AUTOSAR XML (schema 00049)
# Copyright (c) 2018 Vector Informatik GmbH.
standard types defined: boolean, uint8
package /VehicleProject
  system System
package /TP
  lin tp config LIN00: communication-cluster=LIN00
    7 x tp address:
      TA_0x0001: tp-address=1
      TA_0x0002: tp-address=2
      TA_0x0003: tp-address=3
      TA_0x0004: tp-address=4
      TA_0x0005: tp-address=5
      TA_0x0006: tp-address=6
      TA_0x007E: tp-address=126
    tp-connections:
      data-pdu=MasterReq_Tp, lin-tp-n-sdu=MasterReq, multicast=TA_0x007E, receiver=[TN_0x0001_DWF_Left, TN_0x0002_DWR_Left, TN_0x0003_RVM_Left, TN_0x0004_RVM_Right, TN_0x0005_DWR_Right, TN_0x0006_DWF_Right], transmitter=TN_Master
      data-pdu=SlaveResp_Tp, flow-control=MasterReq_Tp, lin-tp-n-sdu=SlaveResp_DWF_Left, receiver=TN_Master, transmitter=TN_0x0001_DWF_Left
      data-pdu=SlaveResp_Tp, flow-control=MasterReq_Tp, lin-tp-n-sdu=SlaveResp_DWR_Left, receiver=TN_Master, transmitter=TN_0x0002_DWR_Left
      data-pdu=SlaveResp_Tp, flow-control=MasterReq_Tp, lin-tp-n-sdu=SlaveResp_RVM_Left, receiver=TN_Master, transmitter=TN_0x0003_RVM_Left
      data-pdu=SlaveResp_Tp, flow-control=MasterReq_Tp, lin-tp-n-sdu=SlaveResp_RVM_Right, receiver=TN_Master, transmitter=TN_0x0004_RVM_Right
      data-pdu=SlaveResp_Tp, flow-control=MasterReq_Tp, lin-tp-n-sdu=SlaveResp_DWR_Right, receiver=TN_Master, transmitter=TN_0x0005_DWR_Right
      data-pdu=SlaveResp_Tp, flow-control=MasterReq_Tp, lin-tp-n-sdu=SlaveResp_DWF_Right, receiver=TN_Master, transmitter=TN_0x0006_DWF_Right
      data-pdu=MasterReq_Tp, flow-control=SlaveResp_Tp, lin-tp-n-sdu=MasterReq_DWF_Left, receiver=TN_0x0001_DWF_Left, transmitter=TN_Master
      data-pdu=MasterReq_Tp, flow-control=SlaveResp_Tp, lin-tp-n-sdu=MasterReq_DWR_Left, receiver=TN_0x0002_DWR_Left, transmitter=TN_Master
      data-pdu=MasterReq_Tp, flow-control=SlaveResp_Tp, lin-tp-n-sdu=MasterReq_RVM_Left, receiver=TN_0x0003_RVM_Left, transmitter=TN_Master
      data-pdu=MasterReq_Tp, flow-control=SlaveResp_Tp, lin-tp-n-sdu=MasterReq_RVM_Right, receiver=TN_0x0004_RVM_Right, transmitter=TN_Master
      data-pdu=MasterReq_Tp, flow-control=SlaveResp_Tp, lin-tp-n-sdu=MasterReq_DWR_Right, receiver=TN_0x0005_DWR_Right, transmitter=TN_Master
      data-pdu=MasterReq_Tp, flow-control=SlaveResp_Tp, lin-tp-n-sdu=MasterReq_DWF_Right, receiver=TN_0x0006_DWF_Right, transmitter=TN_Master
    7 x lin tp node:
      TN_0x0001_DWF_Left: connector=DWF_Left/CN_LIN00, tp-address=TA_0x0001
      TN_0x0002_DWR_Left: connector=DWR_Left/CN_LIN00, tp-address=TA_0x0002
      TN_0x0003_RVM_Left: connector=RVM_Left/CN_LIN00, tp-address=TA_0x0003
      TN_0x0004_RVM_Right: connector=RVM_Right/CN_LIN00, tp-address=TA_0x0004
      TN_0x0005_DWR_Right: connector=DWR_Right/CN_LIN00, tp-address=TA_0x0005
      TN_0x0006_DWF_Right: connector=DWF_Right/CN_LIN00, tp-address=TA_0x0006
      TN_Master: connector=GWI/CN_LIN00
package /Cluster
  lin cluster LIN00: baudrate=19200, protocol-name=LIN, protocol-version=LIN22  # Door | /*************************************************************************************/ // // Description: LIN Description file created using Vector's DaVinci Network Designer // Created: 12 Oct 2007 10:43:53 // Author: Vector Informatik GmbH // Version: 0.1 // /*************************************************************************************/
    lin physical channel CHNL
      comm-connectors:
        DWF_Left/CN_LIN00
        DWF_Right/CN_LIN00
        DWR_Left/CN_LIN00
        DWR_Right/CN_LIN00
        GWI/CN_LIN00
        RVM_Left/CN_LIN00
        RVM_Right/CN_LIN00
      frame DWFL_01: id 0x3, from DWF_Left, to GWI, frame-length=2, lin-checksum=ENHANCED
        pdu DWFL_01: length=2, unused-bit-pattern=255
          signal DWFL_WinPos: start 0, 8 bit, little-endian, i-signal-type=PRIMITIVE, init-value=0, base-type=uint8, compu {identical}, range raw 0..255, to GWI
          signal DWFL_ResponseError: start 8, 1 bit, little-endian, i-signal-type=PRIMITIVE, init-value=0, base-type=boolean, compu {identical}, range raw 0..1, to GWI
      frame DWFR_01: id 0x0, from DWF_Right, to GWI, frame-length=2, lin-checksum=ENHANCED
        pdu DWFR_01: length=2, unused-bit-pattern=255
          signal DWFR_ResponseError: start 0, 1 bit, little-endian, i-signal-type=PRIMITIVE, init-value=0, base-type=boolean, compu {identical}, range raw 0..1, to GWI
          signal DWFR_WinPos: start 8, 8 bit, little-endian, i-signal-type=PRIMITIVE, init-value=0, base-type=uint8, compu {identical}, range raw 0..255, to GWI
      frame DWRL_01: id 0x2, from DWR_Left, to GWI, frame-length=2, lin-checksum=ENHANCED
        pdu DWRL_01: length=2, unused-bit-pattern=255
          signal DWRL_WinPos: start 0, 8 bit, little-endian, i-signal-type=PRIMITIVE, init-value=0, base-type=uint8, compu {identical}, range raw 0..255, to GWI
          signal DWRL_ResponseError: start 8, 1 bit, little-endian, i-signal-type=PRIMITIVE, init-value=0, base-type=boolean, compu {identical}, range raw 0..1, to GWI
      frame DWRR_01: id 0x7, from DWR_Right, to GWI, frame-length=2, lin-checksum=ENHANCED
        pdu DWRR_01: length=2, unused-bit-pattern=255
          signal DWRR_ResponseError: start 0, 1 bit, little-endian, i-signal-type=PRIMITIVE, init-value=0, base-type=boolean, compu {identical}, range raw 0..1, to GWI
          signal DWRR_WinPos: start 8, 8 bit, little-endian, i-signal-type=PRIMITIVE, init-value=0, base-type=uint8, compu {identical}, range raw 0..255, to GWI
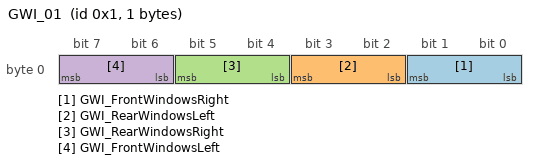
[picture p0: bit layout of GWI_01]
      frame GWI_01: id 0x1, from GWI, to DWF_Left DWF_Right DWR_Left DWR_Right, frame-length=1, lin-checksum=ENHANCED
        pdu GWI_01: length=1, unused-bit-pattern=255
          signal GWI_FrontWindowsRight: start 0, 2 bit, little-endian, i-signal-type=PRIMITIVE, init-value=1, base-type=uint8, compu {0=Cx0_Down, 1=Cx1_Halt, 2=Cx2_Up}, range raw 0..2, to DWF_Right
          signal GWI_RearWindowsLeft: start 2, 2 bit, little-endian, i-signal-type=PRIMITIVE, init-value=1, base-type=uint8, compu {0=Cx0_Down, 1=Cx1_Halt, 2=Cx2_Up}, range raw 0..2, to DWR_Left
          signal GWI_RearWindowsRight: start 4, 2 bit, little-endian, i-signal-type=PRIMITIVE, init-value=1, base-type=uint8, compu {0=Cx0_Down, 1=Cx1_Halt, 2=Cx2_Up}, range raw 0..2, to DWR_Right
          signal GWI_FrontWindowsLeft: start 6, 2 bit, little-endian, i-signal-type=PRIMITIVE, init-value=1, base-type=uint8, compu {0=Cx0_Down, 1=Cx1_Halt, 2=Cx2_Up}, range raw 0..2, to DWF_Left
      frame GWI_02: id 0x4, from GWI, to DWF_Left DWF_Right DWR_Left, frame-length=1, lin-checksum=ENHANCED
        pdu GWI_02: length=1, unused-bit-pattern=255
          signal CLSStatusLeft_oGWI_02: start 0, 1 bit, little-endian, i-signal-type=PRIMITIVE, init-value=0, base-type=boolean, compu {0=Cx0_Close, 1=Cx1_Open}, range raw 0..1, to DWF_Left DWR_Left
          signal CLSStatusRight_oGWI_02: start 1, 1 bit, little-endian, i-signal-type=PRIMITIVE, init-value=0, base-type=boolean, compu {0=Cx0_Close, 1=Cx1_Open}, range raw 0..1, to DWF_Right
      frame GWI_03: id 0x5, from GWI, to RVM_Left RVM_Right, frame-length=1, lin-checksum=ENHANCED
        pdu GWI_03: length=1, unused-bit-pattern=255
          signal GWI_MirrorCommandLeft: start 0, 4 bit, little-endian, i-signal-type=PRIMITIVE, init-value=0, base-type=uint8, compu {0=Cx0_Don_t_move (Don't move), 1=Cx1_Move_left (Move left), 2=Cx2_Move_Up (Move Up), 3=Cx3_Move_Right (Move Right), 4=Cx4_Move_Down (Move Down)}, range raw 0..4, to RVM_Left
          signal GWI_MirrorCommandRight: start 4, 4 bit, little-endian, i-signal-type=PRIMITIVE, init-value=0, base-type=uint8, compu {0=Cx0_Don_t_move (Don't move), 1=Cx1_Move_left (Move left), 2=Cx2_Move_Up (Move Up), 3=Cx3_Move_Right (Move Right), 4=Cx4_Move_Down (Move Down)}, range raw 0..4, to RVM_Right
      frame MasterReq: id 0x3C, from GWI, to DWF_Left DWF_Right DWR_Left DWR_Right RVM_Left RVM_Right, frame-length=8, lin-checksum=CLASSIC
        n pdu MasterReq_Tp: length=8
      frame RVML_01: id 0x6, from RVM_Left, to GWI, frame-length=2, lin-checksum=ENHANCED
        pdu RVML_01: length=2, unused-bit-pattern=255
          signal RVML_MirrorPosition: start 0, 8 bit, little-endian, i-signal-type=PRIMITIVE, init-value=0, base-type=uint8, compu {identical}, range raw 0..255, to GWI
          signal RVML_ResponseError: start 8, 1 bit, little-endian, i-signal-type=PRIMITIVE, init-value=0, base-type=boolean, compu {identical}, range raw 0..1, to GWI
      frame RVMR_01: id 0x8, from RVM_Right, to GWI, frame-length=2, lin-checksum=ENHANCED
        pdu RVMR_01: length=2, unused-bit-pattern=255
          signal RVMR_ResponseError: start 0, 1 bit, little-endian, i-signal-type=PRIMITIVE, init-value=0, base-type=boolean, compu {identical}, range raw 0..1, to GWI
          signal RVMR_MirrorPosition: start 8, 8 bit, little-endian, i-signal-type=PRIMITIVE, init-value=0, base-type=uint8, compu {identical}, range raw 0..255, to GWI
      frame SlaveResp: id 0x3D, from DWF_Left DWF_Right DWR_Left DWR_Right RVM_Left RVM_Right, to GWI, frame-length=8, lin-checksum=CLASSIC
        n pdu SlaveResp_Tp: length=8
      pdu triggering PT_MasterReq: pdu=MasterReq, from GWI, to DWF_Left DWF_Right DWR_Left DWR_Right RVM_Left RVM_Right
      pdu triggering PT_MasterReq_DWF_Left: pdu=MasterReq_DWF_Left, from GWI, to DWF_Left
      pdu triggering PT_MasterReq_DWF_Right: pdu=MasterReq_DWF_Right, from GWI, to DWF_Right
      pdu triggering PT_MasterReq_DWR_Left: pdu=MasterReq_DWR_Left, from GWI, to DWR_Left
      pdu triggering PT_MasterReq_DWR_Right: pdu=MasterReq_DWR_Right, from GWI, to DWR_Right
      pdu triggering PT_MasterReq_RVM_Left: pdu=MasterReq_RVM_Left, from GWI, to RVM_Left
      pdu triggering PT_MasterReq_RVM_Right: pdu=MasterReq_RVM_Right, from GWI, to RVM_Right
      pdu triggering PT_SlaveResp_DWF_Left: pdu=SlaveResp_DWF_Left, from DWF_Left, to GWI
      pdu triggering PT_SlaveResp_DWF_Right: pdu=SlaveResp_DWF_Right, from DWF_Right, to GWI
      pdu triggering PT_SlaveResp_DWR_Left: pdu=SlaveResp_DWR_Left, from DWR_Left, to GWI
      pdu triggering PT_SlaveResp_DWR_Right: pdu=SlaveResp_DWR_Right, from DWR_Right, to GWI
      pdu triggering PT_SlaveResp_RVM_Left: pdu=SlaveResp_RVM_Left, from RVM_Left, to GWI
      pdu triggering PT_SlaveResp_RVM_Right: pdu=SlaveResp_RVM_Right, from RVM_Right, to GWI
      lin schedule table Table0: run-mode=RUN-CONTINUOUS
        table-entrys:
          delay=0.01, position-in-table=0, frame-triggering=FT_MasterReq
          delay=0.01, position-in-table=1, frame-triggering=FT_SlaveResp
      lin schedule table Table1: run-mode=RUN-CONTINUOUS
        table-entrys:
          delay=0.005, position-in-table=0, frame-triggering=FT_DWRR_01
          delay=0.005, position-in-table=1, frame-triggering=FT_DWFL_01
          delay=0.005, position-in-table=2, frame-triggering=FT_DWFR_01
          delay=0.005, position-in-table=3, frame-triggering=FT_DWRL_01
          delay=0.004, position-in-table=4, frame-triggering=FT_GWI_01
          delay=0.004, position-in-table=5, frame-triggering=FT_GWI_02
          delay=0.004, position-in-table=6, frame-triggering=FT_GWI_03
          delay=0.005, position-in-table=7, frame-triggering=FT_RVML_01
          delay=0.005, position-in-table=8, frame-triggering=FT_RVMR_01
package /ECU
  7 x ecu instance:
    DWF_Left: associated-com-i-pdu-group=[DWF_Left_Rx, DWF_Left_Tx]
      lin slave CT_LIN00: protocol-version=LIN22, assign-nad=true, configured-nad=1, function-id=1, initial-nad=1, lin-error-response=ST_DWFL_ResponseError, nas-timeout=1000, supplier-id=30, variant-id=1
      lin communication connector CN_LIN00: comm-controller=DWF_Left/CT_LIN00, initial-nad=1
    DWF_Right: associated-com-i-pdu-group=[DWF_Right_Rx, DWF_Right_Tx]
      lin slave CT_LIN00: protocol-version=LIN21, assign-nad=true, configured-nad=6, function-id=1, initial-nad=6, lin-error-response=ST_DWFR_ResponseError, nas-timeout=1000, supplier-id=30, variant-id=1
      lin communication connector CN_LIN00: comm-controller=DWF_Right/CT_LIN00, initial-nad=6, lin-ordered-configurable-frames=[{frame=DWFR_01, index=0}, {frame=GWI_01, index=1}, {frame=GWI_02, index=2}]
    DWR_Left: associated-com-i-pdu-group=[DWR_Left_Rx, DWR_Left_Tx]
      lin slave CT_LIN00: protocol-version=LIN21, assign-nad=true, configured-nad=2, function-id=1, initial-nad=2, lin-error-response=ST_DWRL_ResponseError, nas-timeout=1000, supplier-id=30, variant-id=1
      lin communication connector CN_LIN00: comm-controller=DWR_Left/CT_LIN00, initial-nad=2, lin-ordered-configurable-frames=[{frame=DWRL_01, index=0}, {frame=GWI_01, index=1}, {frame=GWI_02, index=2}]
    DWR_Right: associated-com-i-pdu-group=[DWR_Right_Rx, DWR_Right_Tx]
      lin slave CT_LIN00: protocol-version=LIN21, assign-nad=true, configured-nad=5, function-id=1, initial-nad=5, lin-error-response=ST_DWRR_ResponseError, nas-timeout=1000, supplier-id=30, variant-id=1
      lin communication connector CN_LIN00: comm-controller=DWR_Right/CT_LIN00, initial-nad=5, lin-ordered-configurable-frames=[{frame=DWRR_01, index=0}, {frame=GWI_01, index=1}]
    GWI: associated-com-i-pdu-group=[GWI_Rx, GWI_Tx]
      lin master CT_LIN00: protocol-version=LIN22, time-base=0.001, time-base-jitter=0
      lin communication connector CN_LIN00: comm-controller=CT_LIN00
    RVM_Left: associated-com-i-pdu-group=[RVM_Left_Rx, RVM_Left_Tx]
      lin slave CT_LIN00: protocol-version=LIN21, assign-nad=true, configured-nad=3, function-id=1, initial-nad=3, lin-error-response=ST_RVML_ResponseError, nas-timeout=1000, supplier-id=30, variant-id=1
      lin communication connector CN_LIN00: comm-controller=RVM_Left/CT_LIN00, initial-nad=3, lin-ordered-configurable-frames=[{frame=GWI_03, index=0}, {frame=RVML_01, index=1}]
    RVM_Right: associated-com-i-pdu-group=[RVM_Right_Rx, RVM_Right_Tx]
      lin slave CT_LIN00: protocol-version=LIN21, assign-nad=true, configured-nad=4, function-id=1, initial-nad=4, lin-error-response=ST_RVMR_ResponseError, nas-timeout=1000, supplier-id=30, variant-id=1
      lin communication connector CN_LIN00: comm-controller=RVM_Right/CT_LIN00, initial-nad=4, lin-ordered-configurable-frames=[{frame=RVMR_01, index=0}, {frame=GWI_03, index=1}]
package /IPDUGroup
  14 x i signal i pdu group:
    DWF_Left_Rx: communication-direction=IN, i-signal-i-pdus=[GWI_01, GWI_02]
    DWF_Left_Tx: communication-direction=OUT, i-signal-i-pdus=DWFL_01
    DWF_Right_Rx: communication-direction=IN, i-signal-i-pdus=[GWI_01, GWI_02]
    DWF_Right_Tx: communication-direction=OUT, i-signal-i-pdus=DWFR_01
    DWR_Left_Rx: communication-direction=IN, i-signal-i-pdus=[GWI_01, GWI_02]
    DWR_Left_Tx: communication-direction=OUT, i-signal-i-pdus=DWRL_01
    DWR_Right_Rx: communication-direction=IN, i-signal-i-pdus=GWI_01
    DWR_Right_Tx: communication-direction=OUT, i-signal-i-pdus=DWRR_01
    GWI_Rx: communication-direction=IN, i-signal-i-pdus=[DWFL_01, DWFR_01, DWRL_01, DWRR_01, RVML_01, RVMR_01]
    GWI_Tx: communication-direction=OUT, i-signal-i-pdus=[GWI_01, GWI_02, GWI_03]
    RVM_Left_Rx: communication-direction=IN, i-signal-i-pdus=GWI_03
    RVM_Left_Tx: communication-direction=OUT, i-signal-i-pdus=RVML_01
    RVM_Right_Rx: communication-direction=IN, i-signal-i-pdus=GWI_03
    RVM_Right_Tx: communication-direction=OUT, i-signal-i-pdus=RVMR_01
package /PDU
  dcm i pdu MasterReq_DWF_Left: length=8, diag-pdu-type=DIAG-REQUEST
  dcm i pdu MasterReq_DWF_Right: length=8, diag-pdu-type=DIAG-REQUEST
  dcm i pdu MasterReq_DWR_Left: length=8, diag-pdu-type=DIAG-REQUEST
  dcm i pdu MasterReq_DWR_Right: length=8, diag-pdu-type=DIAG-REQUEST
  dcm i pdu MasterReq: length=8, diag-pdu-type=DIAG-REQUEST
  dcm i pdu MasterReq_RVM_Left: length=8, diag-pdu-type=DIAG-REQUEST
  dcm i pdu MasterReq_RVM_Right: length=8, diag-pdu-type=DIAG-REQUEST
  dcm i pdu SlaveResp_DWF_Left: length=8, diag-pdu-type=DIAG-RESPONSE
  dcm i pdu SlaveResp_DWF_Right: length=8, diag-pdu-type=DIAG-RESPONSE
  dcm i pdu SlaveResp_DWR_Left: length=8, diag-pdu-type=DIAG-RESPONSE
  dcm i pdu SlaveResp_DWR_Right: length=8, diag-pdu-type=DIAG-RESPONSE
  dcm i pdu SlaveResp_RVM_Left: length=8, diag-pdu-type=DIAG-RESPONSE
  dcm i pdu SlaveResp_RVM_Right: length=8, diag-pdu-type=DIAG-RESPONSE
package /Signal
  16 x system signal, all with compu {identical}, range raw 0..255:
    MasterReqB{0..7}
    SlaveRespB{0..7}
